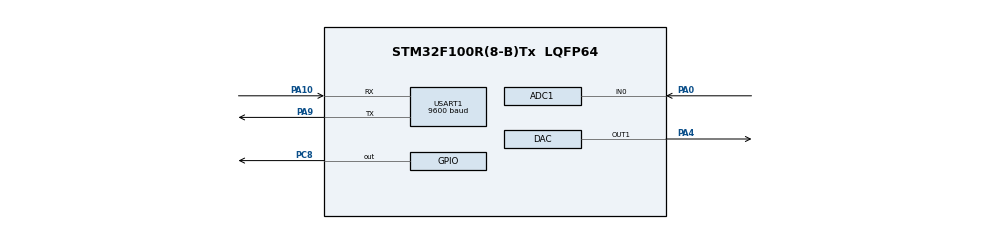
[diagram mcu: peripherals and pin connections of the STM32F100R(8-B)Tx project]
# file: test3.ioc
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ADC1.Channel-6\#ChannelRegularConversion=ADC_CHANNEL_TEMPSENSOR
ADC1.NbrOfConversionFlag=1
ADC1.Rank-6\#ChannelRegularConversion=1
ADC1.SamplingTime-6\#ChannelRegularConversion=ADC_SAMPLETIME_1CYCLE_5
ADC1.master=1
Dma.DAC_CH1.0.Direction=DMA_MEMORY_TO_PERIPH
Dma.DAC_CH1.0.Instance=DMA1_Channel3
Dma.DAC_CH1.0.MemDataAlignment=DMA_MDATAALIGN_BYTE
Dma.DAC_CH1.0.MemInc=DMA_MINC_DISABLE
Dma.DAC_CH1.0.Mode=DMA_NORMAL
Dma.DAC_CH1.0.PeriphDataAlignment=DMA_PDATAALIGN_BYTE
Dma.DAC_CH1.0.PeriphInc=DMA_PINC_DISABLE
Dma.DAC_CH1.0.Priority=DMA_PRIORITY_LOW
Dma.Request0=DAC_CH1
Mcu.Family=STM32F1
Mcu.Name=STM32F100R(8-B)Tx
Mcu.Package=LQFP64
NVIC.DMA1_Channel3_IRQn=true\:0\:0\:false
NVIC.PriorityGroup=NVIC_PRIORITYGROUP_4
PA0-WKUP.Signal=ADCx_IN0
PA10.Mode=Asynchronous
PA10.Signal=USART1_RX
PA4.Signal=COMP_DAC1_group
PA9.Mode=Asynchronous
PA9.Signal=USART1_TX
PC8.Signal=GPIO_Output
ProjectManager.TargetToolchain=TrueSTUDIO 4.3.1
RCC.APB1Freq_Value=8000000
RCC.APB2Freq_Value=8000000
SH.ADCx_IN0.0=ADC1_IN0,IN0
SH.COMP_DAC1_group.0=DAC_OUT1,DAC_OUT1
USART1.BaudRate=9600
VP_ADC1_TempSens_Input.Mode=IN-TempSens
VP_ADC1_Vref_Input.Mode=IN-Vrefint
board=test3

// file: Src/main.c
/**
  ******************************************************************************
  * File Name          : main.c
  * Description        : Main program body
  ******************************************************************************
  *
  * COPYRIGHT(c) 2015 STMicroelectronics
  *
  * Redistribution and use in source and binary forms, with or without modification,
  * are permitted provided that the following conditions are met:
  *   1. Redistributions of source code must retain the above copyright notice,
  *      this list of conditions and the following disclaimer.
  *   2. Redistributions in binary form must reproduce the above copyright notice,
  *      this list of conditions and the following disclaimer in the documentation
  *      and/or other materials provided with the distribution.
  *   3. Neither the name of STMicroelectronics nor the names of its contributors
  *      may be used to endorse or promote products derived from this software
  *      without specific prior written permission.
  *
  * THIS SOFTWARE IS PROVIDED BY THE COPYRIGHT HOLDERS AND CONTRIBUTORS "AS IS"
  * AND ANY EXPRESS OR IMPLIED WARRANTIES, INCLUDING, BUT NOT LIMITED TO, THE
  * IMPLIED WARRANTIES OF MERCHANTABILITY AND FITNESS FOR A PARTICULAR PURPOSE ARE
  * DISCLAIMED. IN NO EVENT SHALL THE COPYRIGHT HOLDER OR CONTRIBUTORS BE LIABLE
  * FOR ANY DIRECT, INDIRECT, INCIDENTAL, SPECIAL, EXEMPLARY, OR CONSEQUENTIAL
  * DAMAGES (INCLUDING, BUT NOT LIMITED TO, PROCUREMENT OF SUBSTITUTE GOODS OR
  * SERVICES; LOSS OF USE, DATA, OR PROFITS; OR BUSINESS INTERRUPTION) HOWEVER
  * CAUSED AND ON ANY THEORY OF LIABILITY, WHETHER IN CONTRACT, STRICT LIABILITY,
  * OR TORT (INCLUDING NEGLIGENCE OR OTHERWISE) ARISING IN ANY WAY OUT OF THE USE
  * OF THIS SOFTWARE, EVEN IF ADVISED OF THE POSSIBILITY OF SUCH DAMAGE.
  *
  ******************************************************************************
  */
#include "stm32f1xx_hal.h"
#include "adc.h"
#include "dac.h"
#include "dma.h"
#include "usart.h"
#include "gpio.h"

void SystemClock_Config(void);

int main(void)
{

  /* MCU Configuration----------------------------------------------------------*/

  /* Reset of all peripherals, Initializes the Flash interface and the Systick. */
  HAL_Init();

  /* Configure the system clock */
  SystemClock_Config();

  /* Initialize all configured peripherals */
  MX_GPIO_Init();
  MX_DMA_Init();
  MX_ADC1_Init();
  MX_DAC_Init();
  MX_USART1_UART_Init();

  /* USER CODE BEGIN 2 */

  //HAL_ADC_Start(hadc1);

  /* USER CODE END 2 */

  /* Infinite loop */
  while (1)
  {

  /* USER CODE BEGIN 3 */

	  //HAL_DAC_SetValue(hdac)

	  HAL_GPIO_WritePin(GPIOC, GPIO_PIN_8, GPIO_PIN_SET);
	  HAL_Delay(500);
	  HAL_GPIO_WritePin(GPIOC, GPIO_PIN_8, GPIO_PIN_RESET);
	  HAL_Delay(500);
  }
  /* USER CODE END 3 */

}

/** System Clock Configuration
*/
void SystemClock_Config(void)
{

  RCC_OscInitTypeDef RCC_OscInitStruct;
  RCC_ClkInitTypeDef RCC_ClkInitStruct;
  RCC_PeriphCLKInitTypeDef PeriphClkInit;

  RCC_OscInitStruct.OscillatorType = RCC_OSCILLATORTYPE_HSI;
  RCC_OscInitStruct.HSIState = RCC_HSI_ON;
  RCC_OscInitStruct.HSICalibrationValue = 16;
  RCC_OscInitStruct.PLL.PLLState = RCC_PLL_NONE;
  HAL_RCC_OscConfig(&RCC_OscInitStruct);

  RCC_ClkInitStruct.ClockType = RCC_CLOCKTYPE_SYSCLK;
  RCC_ClkInitStruct.SYSCLKSource = RCC_SYSCLKSOURCE_HSI;
  RCC_ClkInitStruct.AHBCLKDivider = RCC_SYSCLK_DIV1;
  RCC_ClkInitStruct.APB1CLKDivider = RCC_HCLK_DIV1;
  RCC_ClkInitStruct.APB2CLKDivider = RCC_HCLK_DIV1;
  HAL_RCC_ClockConfig(&RCC_ClkInitStruct, FLASH_LATENCY_0);

  PeriphClkInit.PeriphClockSelection = RCC_PERIPHCLK_ADC;
  PeriphClkInit.AdcClockSelection = RCC_ADCPCLK2_DIV2;
  HAL_RCCEx_PeriphCLKConfig(&PeriphClkInit);

  HAL_SYSTICK_Config(HAL_RCC_GetHCLKFreq()/1000);

  HAL_SYSTICK_CLKSourceConfig(SYSTICK_CLKSOURCE_HCLK);

  /* SysTick_IRQn interrupt configuration */
  HAL_NVIC_SetPriority(SysTick_IRQn, 0, 0);
}

/************************ (C) COPYRIGHT STMicroelectronics *****END OF FILE****/
